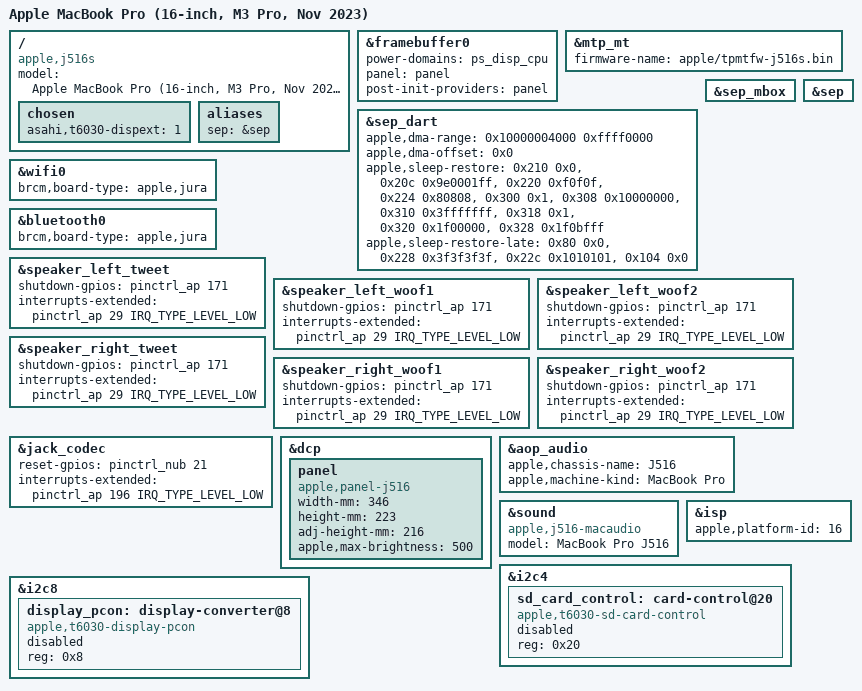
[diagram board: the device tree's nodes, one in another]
// SPDX-License-Identifier: GPL-2.0+ OR MIT
/*
 * MacBook Pro (16-inch, M3 Pro, Nov 2023)
 *
 * target-type: J516s
 *
 * Copyright The Asahi Linux Contributors
 */

/dts-v1/;

#include "t6030.dtsi"
#include "t603x-j514-j516.dtsi"
#include "t603x-j514s-j516s-usb4.dtsi"
#include "t603x-j514s-j516s-hdmi.dtsi"

/ {
	compatible = "apple,j516s", "apple,t6030", "apple,arm-platform";
	model = "Apple MacBook Pro (16-inch, M3 Pro, Nov 2023)";

	chosen {
		asahi,t6030-dispext = "1";
	};
};

&framebuffer0 {
	power-domains = <&ps_disp_cpu>;
	panel = <&panel>;
	post-init-providers = <&panel>;
};

&mtp_mt {
	firmware-name = "apple/tpmtfw-j516s.bin";
};

/*
 * The SEP, for its sleep only (apple_sep's T6030/J516s profile brings up nothing else). The
 * alias makes the loader publish its manifests on the node. SID 0's window is the one the
 * 26B123 ioreg records for dart-sep (vm-base 0x10000004000, vm-size 0xffff0000), present
 * before the DART probes.
 */
/ {
	aliases {
		sep = &sep;
	};
};

&sep_dart {
	apple,dma-range = /bits/ 64 <0x10000004000 0xffff0000>;
	apple,dma-offset = /bits/ 64 <0x0>;
	/*
	 * What macOS 27.2 writes to this DART at the wake (the t5 trace), as offset and value:
	 * the config words, SID 0's TCR and TTBR, a TLB flush, the late config words, the error
	 * mask, then the streams. The config words go back as Linux had them before the sleep,
	 * and SID 0 and the streams as Linux saved them; the lists give the order around them.
	 */
	apple,sleep-restore = <0x210 0x0>, <0x20c 0x9e0001ff>,
			      <0x220 0xf0f0f>, <0x224 0x80808>,
			      <0x300 0x1>, <0x308 0x10000000>,
			      <0x310 0x3fffffff>, <0x318 0x1>,
			      <0x320 0x1f00000>, <0x328 0x1f0bfff>;
	apple,sleep-restore-late = <0x80 0x0>, <0x228 0x3f3f3f3f>,
				   <0x22c 0x1010101>, <0x104 0x0>;
	status = "okay";
};

&sep_mbox {
	status = "okay";
};

&sep {
	status = "okay";
};

&wifi0 {
	brcm,board-type = "apple,jura";
};

&bluetooth0 {
	brcm,board-type = "apple,jura";
};

&speaker_left_tweet {
	shutdown-gpios = <&pinctrl_ap 171 GPIO_ACTIVE_HIGH>;
	interrupts-extended = <&pinctrl_ap 29 IRQ_TYPE_LEVEL_LOW>;
};

&speaker_left_woof1 {
	shutdown-gpios = <&pinctrl_ap 171 GPIO_ACTIVE_HIGH>;
	interrupts-extended = <&pinctrl_ap 29 IRQ_TYPE_LEVEL_LOW>;
};

&speaker_left_woof2 {
	shutdown-gpios = <&pinctrl_ap 171 GPIO_ACTIVE_HIGH>;
	interrupts-extended = <&pinctrl_ap 29 IRQ_TYPE_LEVEL_LOW>;
};

&speaker_right_tweet {
	shutdown-gpios = <&pinctrl_ap 171 GPIO_ACTIVE_HIGH>;
	interrupts-extended = <&pinctrl_ap 29 IRQ_TYPE_LEVEL_LOW>;
};

&speaker_right_woof1 {
	shutdown-gpios = <&pinctrl_ap 171 GPIO_ACTIVE_HIGH>;
	interrupts-extended = <&pinctrl_ap 29 IRQ_TYPE_LEVEL_LOW>;
};

&speaker_right_woof2 {
	shutdown-gpios = <&pinctrl_ap 171 GPIO_ACTIVE_HIGH>;
	interrupts-extended = <&pinctrl_ap 29 IRQ_TYPE_LEVEL_LOW>;
};

&jack_codec {
	reset-gpios = <&pinctrl_nub 21 GPIO_ACTIVE_HIGH>;
	interrupts-extended = <&pinctrl_ap 196 IRQ_TYPE_LEVEL_LOW>;
};

&dcp {
	panel: panel {
		compatible = "apple,panel-j516", "apple,panel-mini-led", "apple,panel";
		width-mm = <346>;
		height-mm = <223>;
		adj-height-mm = <216>;
		apple,max-brightness = <500>;
	};
};

&aop_audio {
	apple,chassis-name = "J516";
	apple,machine-kind = "MacBook Pro";
};

&sound {
	compatible = "apple,j516-macaudio", "apple,j316-macaudio", "apple,macaudio";
	model = "MacBook Pro J516";
};

&isp {
	apple,platform-id = <16>;
};


&i2c4 {
	sd_card_control: card-control@20 {
		compatible = "apple,t6030-sd-card-control", "apple,sd-card-control";
		reg = <0x20>;
		status = "disabled";
	};
};

&i2c8 {
	display_pcon: display-converter@8 {
		compatible = "apple,t6030-display-pcon", "apple,display-pcon";
		reg = <0x8>;
		status = "disabled";
	};
};
